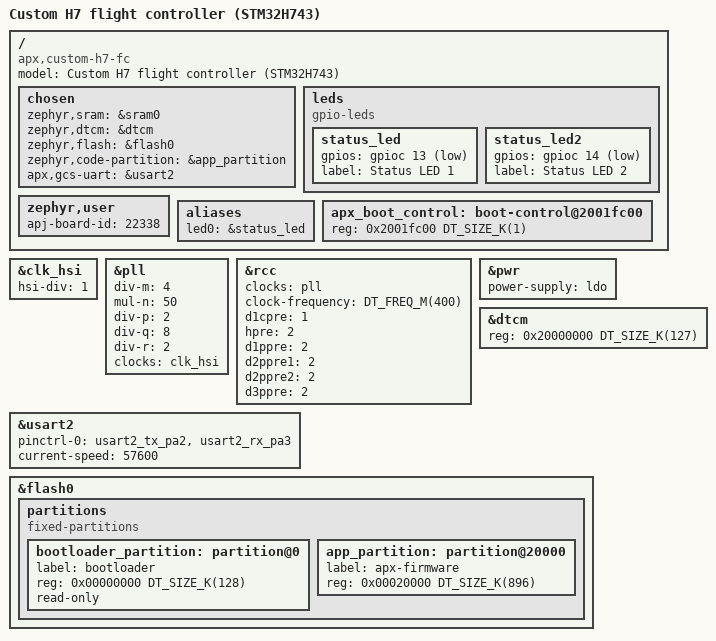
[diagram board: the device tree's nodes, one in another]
/*
 * SPDX-License-Identifier: CC-BY-NC-4.0
 * Copyright (c) 2026 Savita Pawar <savitapawar0402@gmail.com>
 * Author: Savita Pawar (SVPR94)
 * Created: 2026
 *
 * Custom H7 flight controller (STM32H743, Cortex-M7 at 400 MHz).
 *
 * Pins from platforms/stm32h7/boards/custom_h7_fc/hwdef.dat. 128 KB APX
 * bootloader at the start of flash (.apj board id 22338, provisional); the
 * first install is the combined bootloader + firmware image over SWD. The GCS link is
 * the TELEM UART.
 */
/dts-v1/;
#include <st/h7/stm32h743Xi.dtsi>
#include <st/h7/stm32h743xihx-pinctrl.dtsi>
#include <zephyr/dt-bindings/gpio/gpio.h>

/ {
	model = "Custom H7 flight controller (STM32H743)";
	compatible = "apx,custom-h7-fc";

	chosen {
		zephyr,sram = &sram0;
		zephyr,dtcm = &dtcm;
		zephyr,flash = &flash0;
		zephyr,code-partition = &app_partition;
		apx,gcs-uart = &usart2;
	};

	leds {
		compatible = "gpio-leds";
		status_led: status_led {
			gpios = <&gpioc 13 GPIO_ACTIVE_LOW>;
			label = "Status LED 1";
		};
		status_led2: status_led2 {
			gpios = <&gpioc 14 GPIO_ACTIVE_LOW>;
			label = "Status LED 2";
		};
	};

	/* APX board properties - see platforms/zephyr/app/src/board_zephyr.cpp */
	zephyr,user {
		apj-board-id = <22338>; /* provisional: register before release */
	};

	aliases {
		led0 = &status_led;
	};

	/* APX boot control: application <-> bootloader handshake across a
	 * reset (bootloader/include/apx/bootloader/boot_control.hpp). The last
	 * 1 KB of DTCM, outside both images' RAM (&dtcm is shrunk below) and
	 * never cached. */
	apx_boot_control: boot-control@2001fc00 {
		reg = <0x2001fc00 DT_SIZE_K(1)>;
	};
};

/*
 * Clock from the internal 64 MHz HSI: the board sources disagree on the
 * crystal (hwdef.dat 25 MHz, board_config.hpp 8 MHz), and the HSI gives
 * the same 400 MHz on either. Switch to &clk_hse once the crystal is
 * confirmed on the hardware.
 * 64 MHz / 4 = 16 MHz PLL input, * 50 = 800 MHz VCO, / 2 = 400 MHz SYSCLK (VOS1).
 */
&clk_hsi {
	hsi-div = <1>;
	status = "okay";
};

&pll {
	div-m = <4>;
	mul-n = <50>;
	div-p = <2>;
	div-q = <8>;
	div-r = <2>;
	clocks = <&clk_hsi>;
	status = "okay";
};

&rcc {
	clocks = <&pll>;
	clock-frequency = <DT_FREQ_M(400)>;
	d1cpre = <1>;
	hpre = <2>;
	d1ppre = <2>;
	d2ppre1 = <2>;
	d2ppre2 = <2>;
	d3ppre = <2>;
};

/* STM32H743: internal LDO core supply (no SMPS on this part). */
&pwr {
	power-supply = "ldo";
};

/* GCS link: TELEM port (MAVLink), as in hwdef.dat */
&usart2 {
	pinctrl-0 = <&usart2_tx_pa2 &usart2_rx_pa3>;
	pinctrl-names = "default";
	current-speed = <57600>;
	status = "okay";
};

/* Last 1 KB of DTCM reserved for apx_boot_control. */
&dtcm {
	reg = <0x20000000 DT_SIZE_K(127)>;
};

&flash0 {
	partitions {
		compatible = "fixed-partitions";
		#address-cells = <1>;
		#size-cells = <1>;

		/* APX bootloader (built with the firmware, flashed once over SWD) */
		bootloader_partition: partition@0 {
			label = "bootloader";
			reg = <0x00000000 DT_SIZE_K(128)>;
			read-only;
		};
		/* APX firmware: the bootloader starts it at 0x08020000 */
		app_partition: partition@20000 {
			label = "apx-firmware";
			reg = <0x00020000 DT_SIZE_K(896)>;
		};
	};
};
